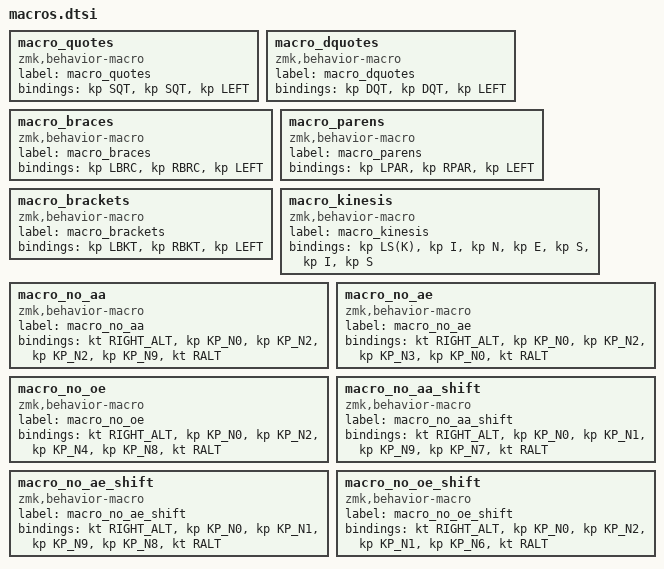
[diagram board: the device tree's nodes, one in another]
macro_quotes: macro_quotes{
compatible = "zmk,behavior-macro";
label = "macro_quotes";
#binding-cells = <0>;
bindings = <&kp SQT>, <&kp SQT>, <&kp LEFT>;
};
macro_dquotes: macro_dquotes{
compatible = "zmk,behavior-macro";
label = "macro_dquotes";
#binding-cells = <0>;
bindings = <&kp DQT>, <&kp DQT>, <&kp LEFT>;
};
macro_braces: macro_braces{
compatible = "zmk,behavior-macro";
label = "macro_braces";
#binding-cells = <0>;
bindings = <&kp LBRC>, <&kp RBRC>, <&kp LEFT>;
};
macro_parens: macro_parens{
compatible = "zmk,behavior-macro";
label = "macro_parens";
#binding-cells = <0>;
bindings = <&kp LPAR>, <&kp RPAR>, <&kp LEFT>;
};
macro_brackets: macro_brackets{
compatible = "zmk,behavior-macro";
label = "macro_brackets";
#binding-cells = <0>;
bindings = <&kp LBKT>, <&kp RBKT>, <&kp LEFT>;
};
macro_kinesis: macro_kinesis{
compatible = "zmk,behavior-macro";
label = "macro_kinesis";
#binding-cells = <0>;
bindings = <&kp LS(K)>, <&kp I>, <&kp N>, <&kp E>, <&kp S>, <&kp I>, <&kp S>;
};
macro_no_aa: macro_no_aa{
compatible = "zmk,behavior-macro";
label = "macro_no_aa";
#binding-cells = <0>;
bindings = <&kt RIGHT_ALT>, <&kp KP_N0>, <&kp KP_N2>, <&kp KP_N2>, <&kp KP_N9>, <&kt RALT>;
};
macro_no_ae: macro_no_ae{
compatible = "zmk,behavior-macro";
label = "macro_no_ae";
#binding-cells = <0>;
bindings = <&kt RIGHT_ALT>, <&kp KP_N0>, <&kp KP_N2>, <&kp KP_N3>, <&kp KP_N0>, <&kt RALT>;
};
macro_no_oe: macro_no_oe{
compatible = "zmk,behavior-macro";
label = "macro_no_oe";
#binding-cells = <0>;
bindings = <&kt RIGHT_ALT>, <&kp KP_N0>, <&kp KP_N2>, <&kp KP_N4>, <&kp KP_N8>, <&kt RALT>;
};
macro_no_aa_shift: macro_no_aa_shift{
compatible = "zmk,behavior-macro";
label = "macro_no_aa_shift";
#binding-cells = <0>;
bindings = <&kt RIGHT_ALT>, <&kp KP_N0>, <&kp KP_N1>, <&kp KP_N9>, <&kp KP_N7>, <&kt RALT>;
};
macro_no_ae_shift: macro_no_ae_shift{
compatible = "zmk,behavior-macro";
label = "macro_no_ae_shift";
#binding-cells = <0>;
bindings = <&kt RIGHT_ALT>, <&kp KP_N0>, <&kp KP_N1>, <&kp KP_N9>, <&kp KP_N8>, <&kt RALT>;
};
macro_no_oe_shift: macro_no_oe_shift{
compatible = "zmk,behavior-macro";
label = "macro_no_oe_shift";
#binding-cells = <0>;
bindings = <&kt RIGHT_ALT>, <&kp KP_N0>, <&kp KP_N2>, <&kp KP_N1>, <&kp KP_N6>, <&kt RALT>;
};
